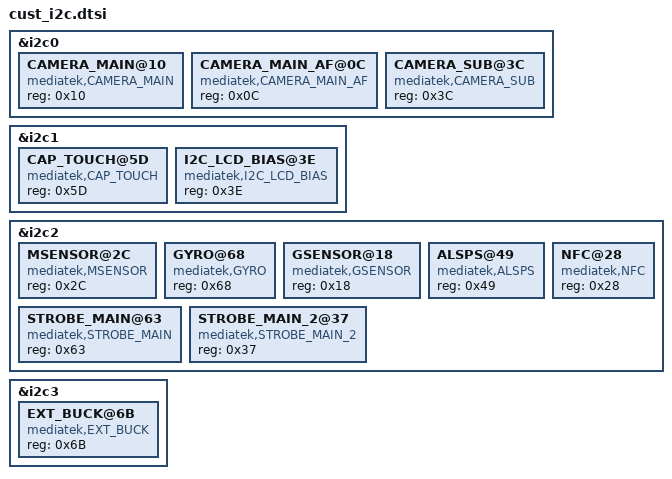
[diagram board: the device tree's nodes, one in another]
/*
 * Generated by MTK SP DrvGen Version 03.13.6 for MT6735M. Copyright MediaTek Inc. (C) 2013.
 * Mon Dec 12 14:28:29 2016
 * Do Not Modify the File.
 */

/*************************
 * I2C DTSI File
*************************/

&i2c0 {
	CAMERA_MAIN@10 {
		compatible = "mediatek,CAMERA_MAIN";
		reg = <0x10>;
	};

	CAMERA_MAIN_AF@0C {
		compatible = "mediatek,CAMERA_MAIN_AF";
		reg = <0x0C>;
	};

	CAMERA_SUB@3C {
		compatible = "mediatek,CAMERA_SUB";
		reg = <0x3C>;
	};

};

&i2c1 {
	CAP_TOUCH@5D {
		compatible = "mediatek,CAP_TOUCH";
		reg = <0x5D>;
	};

	I2C_LCD_BIAS@3E {
		compatible = "mediatek,I2C_LCD_BIAS";
		reg = <0x3E>;
	};

};

&i2c2 {
	MSENSOR@2C {
		compatible = "mediatek,MSENSOR";
		reg = <0x2C>;
	};

	GYRO@68 {
		compatible = "mediatek,GYRO";
		reg = <0x68>;
	};

	GSENSOR@18 {
		compatible = "mediatek,GSENSOR";
		reg = <0x18>;
	};

	ALSPS@49 {
		compatible = "mediatek,ALSPS";
		reg = <0x49>;
	};

	NFC@28 {
		compatible = "mediatek,NFC";
		reg = <0x28>;
	};

	STROBE_MAIN@63 {
		compatible = "mediatek,STROBE_MAIN";
		reg = <0x63>;
	};

	STROBE_MAIN_2@37 {
		compatible = "mediatek,STROBE_MAIN_2";
		reg = <0x37>;
	};

};

&i2c3 {
	EXT_BUCK@6B {
		compatible = "mediatek,EXT_BUCK";
		reg = <0x6B>;
	};

};

